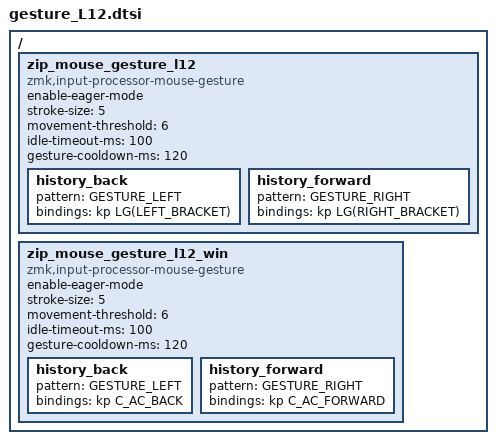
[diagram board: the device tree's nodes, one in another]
/ {
    zip_mouse_gesture_l12: zip_mouse_gesture_l12 {
        compatible = "zmk,input-processor-mouse-gesture";
        #input-processor-cells = <0>;
        enable-eager-mode;
        stroke-size = <5>;
        movement-threshold = <6>;
        idle-timeout-ms = <100>;
        gesture-cooldown-ms = <120>;

        history_back { pattern = <GESTURE_LEFT>; bindings = <&kp LG(LEFT_BRACKET)>; };
        history_forward { pattern = <GESTURE_RIGHT>; bindings = <&kp LG(RIGHT_BRACKET)>; };
    };

    zip_mouse_gesture_l12_win: zip_mouse_gesture_l12_win {
        compatible = "zmk,input-processor-mouse-gesture";
        #input-processor-cells = <0>;
        enable-eager-mode;
        stroke-size = <5>;
        movement-threshold = <6>;
        idle-timeout-ms = <100>;
        gesture-cooldown-ms = <120>;

        history_back { pattern = <GESTURE_LEFT>; bindings = <&kp C_AC_BACK>; };
        history_forward { pattern = <GESTURE_RIGHT>; bindings = <&kp C_AC_FORWARD>; };
    };
};
